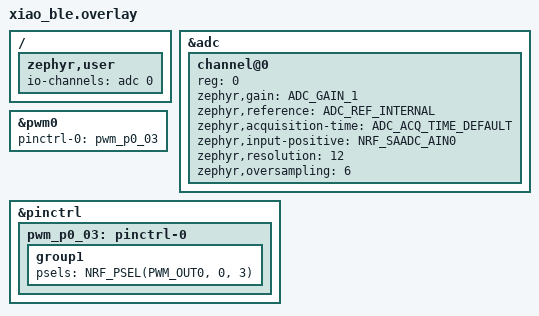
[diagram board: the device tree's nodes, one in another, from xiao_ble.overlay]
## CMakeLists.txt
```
# SPDX-License-Identifier: Apache-2.0

cmake_minimum_required(VERSION 3.20.0)

find_package(Zephyr REQUIRED HINTS $ENV{ZEPHYR_BASE})
project(mtu_update)

target_sources(app PRIVATE
  src/main.c
  src/peripheral_mtu_update.c
  src/emg.c
  src/haptics.c
  src/heartbeat.c
  src/butterworth.c
)
target_include_directories(app PRIVATE inc)
```

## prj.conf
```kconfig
# Bluetooth
CONFIG_BT=y
CONFIG_BT_PERIPHERAL=y
CONFIG_BT_DEVICE_NAME="nemo"

CONFIG_LOG=y
CONFIG_BT_L2CAP_LOG_LEVEL_DBG=y

# App GPIO
CONFIG_PWM=y
CONFIG_ADC=y
CONFIG_GPIO=y

# DSP
# CONFIG_CMSIS_DSP=y
# CONFIG_FPU=y

# HCI ACL buffers size
# BT_L2CAP_RX_MTU = CONFIG_BT_BUF_ACL_RX_SIZE - BT_L2CAP_HDR_SIZE
CONFIG_BT_BUF_ACL_RX_SIZE=251

# L2CAP SDU/PDU TX MTU
CONFIG_BT_L2CAP_TX_MTU=247
```

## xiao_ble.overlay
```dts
/ {
	zephyr,user {
		io-channels = <&adc 0>;
	};
};

&adc {
	#address-cells = <1>;
	#size-cells = <0>;

	channel@0 {
		reg = <0>;
		zephyr,gain = "ADC_GAIN_1";
		zephyr,reference = "ADC_REF_INTERNAL";
		zephyr,acquisition-time = <ADC_ACQ_TIME_DEFAULT>;
		zephyr,input-positive = <NRF_SAADC_AIN0>;
		zephyr,resolution = <12>;
        zephyr,oversampling = <6>;
	};
};

&pwm0 {
    pinctrl-0 = <&pwm_p0_03>;
    /delete-property/ pinctrl-1;
    pinctrl-names = "default";
};

&pinctrl {
    pwm_p0_03: pinctrl-0 {
        group1 {
            psels = <NRF_PSEL(PWM_OUT0, 0, 3)>;
        };
    };
};
```

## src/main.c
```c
/* main.c - Application main entry point */

/*
 * Copyright (c) 2023 Nordic Semiconductor ASA
 *
 * SPDX-License-Identifier: Apache-2.0
 */

#include "peripheral_mtu_update.h"
#include "app_packet.h"
#include "emg.h"
#include "haptics.h"
#include "heartbeat.h"
#include "butterworth.h"

#include <stdint.h>
#include <stdbool.h>

#include <zephyr/kernel.h>
#include <zephyr/sys/printk.h>
#include <zephyr/drivers/gpio.h>

#define ADC_SAMPLE_BUFFER_SIZE 64
#define BUZZER_PERIOD 1000
#define BUZZER_INTENSITY 500
#define BUZZER_THRESH 0x40

static void do_we_buzz(uint8_t power)
{
	if (power > BUZZER_THRESH) {
		gpio_pin_set_dt(&leds[LED_GREEN], 1);
		buzzer_on(BUZZER_INTENSITY);
	} else {
		gpio_pin_set_dt(&leds[LED_GREEN], 0);
		buzzer_off();
	}
}

int main(void)
{
	int i = 0;
	ble_packet_t packet = {0};
	int16_t adc_value = 0;
	int32_t adc_filt_values[ADC_SAMPLE_BUFFER_SIZE] = {0};
	int32_t adc_filt_filt_max = 0;
	int32_t adc_filt_max = 0;
	uint8_t power_rough = 0;

	heartbeat_init(200, LED_BLUE);
	send_peripheral_init();
	adc_init();
	buzzer_init(BUZZER_PERIOD);
	filter_init();

	while (true) {
		heartbeat_beat();
		
		if (adc_sample(&adc_value)) runtime_error();
		adc_filt_values[i % ADC_SAMPLE_BUFFER_SIZE] = (int32_t)adc_value;

		if (i % ADC_SAMPLE_BUFFER_SIZE == 0) {
			// we've filled the buffer, so average and ship it
			adc_filt_max = array_max(adc_filt_values, ADC_SAMPLE_BUFFER_SIZE);
			adc_filt_filt_max = filter(adc_filt_max);
			power_rough = map_to_u8(adc_filt_filt_max, 0, 255);

			// send packet & do haptics response
			do_we_buzz(power_rough);
			packet.data.gesture = power_rough;
			send_peripheral_sample(packet.raw, sizeof(packet.raw), 0);
		}

		i++;
		k_sleep(K_MSEC(1));
	}
	
	return 0;
}
```

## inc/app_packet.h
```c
#pragma once

#include <stdint.h>
#include <assert.h>

struct __attribute__((packed)) tri_axial {
    int16_t x;
    int16_t y;
    int16_t z;
};

struct __attribute__((packed)) ble_data_fields {
    uint16_t gesture;
    struct tri_axial accel;
    struct tri_axial gyro;
};

typedef union ble_data_pack {
    struct ble_data_fields data;
    uint8_t raw[20];
} ble_packet_t;
```

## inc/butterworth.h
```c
#pragma once

#include <stdint.h>

#define OFFSET_FILT_COEF_NUM 1
#define OFFSET_FILT_COEF_DEN 64
#define VAL_FILT_COEF_NUM 1
#define VAL_FILT_COEF_DEN 4

int filter_init();
int32_t filter(int32_t val);
int array_average(int32_t *buf, uint32_t len);
int array_max(int32_t *buf, uint32_t len);
uint8_t map_to_u8(int32_t val, int32_t min, int32_t max);
```

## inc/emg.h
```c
#pragma once

#include <stdint.h>

int adc_sample(int16_t *adc_value);
int adc_init(void);
```

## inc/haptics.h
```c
#pragma once

#include <stdint.h>

int buzzer_init(uint32_t pd);
int buzzer_on(uint32_t pulse_width);
int buzzer_off();
```

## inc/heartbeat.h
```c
#pragma once

#include <zephyr/drivers/gpio.h>
#include <stdint.h>

enum board_led {
    LED_RED = 0,
    LED_GREEN,
    LED_BLUE,
    LED_NUM_LEDS,
};

extern const struct gpio_dt_spec leds[LED_NUM_LEDS];

int heartbeat_init(uint32_t pd_iters, int hb_led);
int heartbeat_beat(void);
void runtime_error(void);
```

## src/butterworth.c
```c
#include "butterworth.h"

static int32_t offset = 0;
static int32_t curr_val = 0;

int filter_init() {
    offset = 0;
    curr_val = 0;
    return 0;
}

int32_t filter(int32_t raw) {
    // calculate two EWMAs -- one for the offset and one for the value
    // advance them at different rates, so offset slowly follows the value

    offset = ((OFFSET_FILT_COEF_DEN - OFFSET_FILT_COEF_NUM) * offset
             + OFFSET_FILT_COEF_NUM * raw) / OFFSET_FILT_COEF_DEN;
    curr_val = ((VAL_FILT_COEF_DEN - VAL_FILT_COEF_NUM) * curr_val
               + VAL_FILT_COEF_NUM * raw) / VAL_FILT_COEF_DEN;

    return curr_val - offset;
}

int array_average(int32_t *buf, uint32_t len) {
    int32_t sum = 0;
    for (int i = 0; i < len; i++) {
        sum += buf[i];
    }
    return sum / len;
}

int array_max(int32_t *buf, uint32_t len) {
    int32_t max = buf[0];
    for (int i = 1; i < len; i++) {
        if (buf[i] > max) {
            max = buf[i];
        }
    }
    return max;
}

uint8_t map_to_u8(int32_t val, int32_t min, int32_t max) {
    if (val < min) {
        return 0;
    } else if (val > max) {
        return 255;
    }
    return (uint8_t)((val - min) * 255 / (max - min));
}
```

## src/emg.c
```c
#include <zephyr/drivers/adc.h>
#include <zephyr/sys/printk.h>
#include "emg.h"

static const struct adc_dt_spec adc_channel = ADC_DT_SPEC_GET(DT_PATH(zephyr_user));

static int16_t adc_buffer[1];
static struct adc_sequence adc_sequence = {
    .buffer = adc_buffer,
    .buffer_size = sizeof(adc_buffer),
};

int adc_sample(int16_t *adc_value)
{
    int err = adc_read(adc_channel.dev, &adc_sequence);
    if (err) {
        printk("ADC read failed %d\n", err);
        return 1;
    }

    *adc_value = adc_buffer[0];
    return 0;
}

int adc_init(void)
{   
    int err;

    if (!adc_is_ready_dt(&adc_channel)) {
        printk("ADC device not ready\n");
        return 1;
    }

    err = adc_channel_setup_dt(&adc_channel);
    if (err < 0) {
        printk("ADC channel setup failed %d\n", err);
        return 1;
    }

    err = adc_sequence_init_dt(&adc_channel, &adc_sequence);
    if (err < 0) {
        printk("ADC sequence init failed %d\n", err);
        return 1;
    }

    return 0;
}
```

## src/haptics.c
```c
#include "haptics.h"

#include <zephyr/drivers/pwm.h>
#include <zephyr/sys/printk.h>

static const struct pwm_dt_spec buzzer = PWM_DT_SPEC_GET(DT_NODELABEL(pwm_led0));

static uint32_t pwm_period_ns;

int buzzer_init(uint32_t pd)
{
    pwm_period_ns = pd;

    if (!pwm_is_ready_dt(&buzzer)) {
        printk("PWM device not ready\n");
        return 1;
    }

    return 0;
}

int buzzer_on(uint32_t pulse_width) {
    int err;

    err = pwm_set_dt(&buzzer, pwm_period_ns, pwm_period_ns - pulse_width);
    if (err) {
        printk("PWM set failed %d\n", err);
        return 1;
    }

    return 0;
}

int buzzer_off() {
    return buzzer_on(0);
}
```

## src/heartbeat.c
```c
#include "heartbeat.h"

#include <zephyr/kernel.h>


#define LED0_NODE DT_ALIAS(led0)
#define LED1_NODE DT_ALIAS(led1)
#define LED2_NODE DT_ALIAS(led2)

const struct gpio_dt_spec leds[LED_NUM_LEDS] = {
	[LED_RED] = GPIO_DT_SPEC_GET(LED0_NODE, gpios),
	[LED_GREEN] = GPIO_DT_SPEC_GET(LED1_NODE, gpios),
	[LED_BLUE] = GPIO_DT_SPEC_GET(LED2_NODE, gpios),
};

static uint32_t heartbeat_pd_iters;
static int heartbeat_led;

void runtime_error(void)
{
	gpio_pin_set_dt(&leds[LED_RED], 1);
	k_sleep(K_FOREVER);
}

int heartbeat_init(uint32_t pd_iters, int hb_led)
{
    heartbeat_pd_iters = pd_iters;
    heartbeat_led = hb_led;

    for (int i = 0; i < ARRAY_SIZE(leds); i++) {
        if (!gpio_is_ready_dt(&leds[i])) {
            return 1;
        }
        gpio_pin_configure_dt(&leds[i], GPIO_OUTPUT_ACTIVE);
        gpio_pin_set_dt(&leds[i], 0);
    }

    return 0;
}

int heartbeat_beat(void)
{
    static int i = 0;

    if (i % heartbeat_pd_iters == 0) {
        gpio_pin_toggle_dt(&leds[heartbeat_led]);
    }

    i++;
    return 0;
}
```

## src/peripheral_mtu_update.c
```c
/*
 * Copyright (c) 2023 Nordic Semiconductor ASA
 *
 * SPDX-License-Identifier: Apache-2.0
 */

#include "peripheral_mtu_update.h"

#include <zephyr/bluetooth/gatt.h>
#include <zephyr/kernel.h>
#include <stddef.h>
#include <stdint.h>
#include <zephyr/sys/printk.h>

#include <zephyr/bluetooth/bluetooth.h>
#include <zephyr/bluetooth/uuid.h>
#include <zephyr/sys/util.h>

#define MTU_TEST_SERVICE_TYPE BT_UUID_128_ENCODE(0x2e2b8dc3, 0x06e0, 0x4f93, 0x9bb2, 0x734091c356f0)

static struct bt_uuid_128 mtu_test_service = BT_UUID_INIT_128(MTU_TEST_SERVICE_TYPE);

static struct bt_uuid_128 notify_characteristic_uuid =
	BT_UUID_INIT_128(BT_UUID_128_ENCODE(0xdeadbeef, 0xdead, 0xbeef, 0xdead, 0xbeefdeadbeef));

static const struct bt_data adv_ad_data[] = {
	BT_DATA_BYTES(BT_DATA_FLAGS, (BT_LE_AD_GENERAL | BT_LE_AD_NO_BREDR)),
	BT_DATA_BYTES(BT_DATA_UUID128_ALL, MTU_TEST_SERVICE_TYPE)};

static void ccc_cfg_changed(const struct bt_gatt_attr *attr, uint16_t value)
{
	ARG_UNUSED(attr);

	bool notif_enabled = (value == BT_GATT_CCC_NOTIFY);

	printk("MTU Test Update: notifications %s\n", notif_enabled ? "enabled" : "disabled");
}

BT_GATT_SERVICE_DEFINE(mtu_test, BT_GATT_PRIMARY_SERVICE(&mtu_test_service),
		       BT_GATT_CHARACTERISTIC(&notify_characteristic_uuid.uuid, BT_GATT_CHRC_NOTIFY,
					      BT_GATT_PERM_NONE, NULL, NULL, NULL),
		       BT_GATT_CCC(ccc_cfg_changed, BT_GATT_PERM_READ | BT_GATT_PERM_WRITE));

void mtu_updated(struct bt_conn *conn, uint16_t tx, uint16_t rx)
{
	printk("Updated MTU: TX: %d RX: %d bytes\n", tx, rx);
}

static struct bt_gatt_cb gatt_callbacks = {.att_mtu_updated = mtu_updated};
static struct bt_gatt_attr *notify_crch = {0};

int send_peripheral_init()
{
	int err;

	err = bt_enable(NULL);
	if (err) {
		printk("Bluetooth init failed (err %d)\n", err);
		return err;
	}

	bt_gatt_cb_register(&gatt_callbacks);

	notify_crch = bt_gatt_find_by_uuid
		(mtu_test.attrs, 0xffff, &notify_characteristic_uuid.uuid
	);

	/* Advertise. Auto include name in adv data. Connectable. */
	err = bt_le_adv_start(BT_LE_ADV_CONN_NAME, adv_ad_data, ARRAY_SIZE(adv_ad_data), NULL, 0);

	printk("Advertising %s\n", err == 0 ? "started" : "failed");
	return err;
}

int send_peripheral_sample(uint8_t *notify_data, size_t notify_data_size, uint16_t seconds)
{
	return bt_gatt_notify(NULL, notify_crch, notify_data, notify_data_size);
}
```
